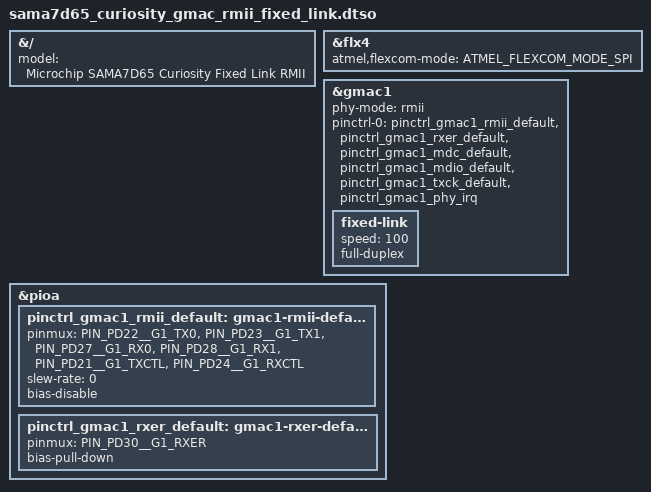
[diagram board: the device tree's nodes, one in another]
// SPDX-License-Identifier: (GPL-2.0+ OR MIT)
/*
 *  Device Tree overlay for the SAMA7D65-CURIOSITY board
 *  to use fixed link RMII.
 *
 *  Copyright (c) 2026 Microchip Technology Inc. and its subsidiaries
 *
 *  Author: Joemel John A. Diente <JoemelJohn.Diente@microchip.com>
 *
 */
/dts-v1/;
/plugin/;
#include "sama7d65-pinfunc.h"
#include <dt-bindings/mfd/atmel-flexcom.h>
#include <dt-bindings/clock/at91.h>
#include <dt-bindings/pinctrl/at91.h>
#include <dt-bindings/gpio/gpio.h>
#include <dt-bindings/interrupt-controller/irq.h>

&{/}
{
	model = "Microchip SAMA7D65 Curiosity Fixed Link RMII";
};

&flx4 {
	atmel,flexcom-mode = <ATMEL_FLEXCOM_MODE_SPI>;
	status = "okay";
};

&gmac1 {
	phy-mode = "rmii";
	pinctrl-names = "default";
	pinctrl-0 = <&pinctrl_gmac1_rmii_default
		     &pinctrl_gmac1_rxer_default
		     &pinctrl_gmac1_mdc_default
		     &pinctrl_gmac1_mdio_default
		     &pinctrl_gmac1_txck_default
		     &pinctrl_gmac1_phy_irq>;
	// cdns,refclk-ext;
	status = "okay";

	fixed-link {
		speed = <100>;
		full-duplex;
	};
};

&pioa {
	pinctrl_gmac1_rmii_default: gmac1-rmii-default{
		pinmux = <PIN_PD22__G1_TX0>,
			 <PIN_PD23__G1_TX1>,
			 <PIN_PD27__G1_RX0>,
			 <PIN_PD28__G1_RX1>,
			 <PIN_PD21__G1_TXCTL>,
			 <PIN_PD24__G1_RXCTL>;
		slew-rate = <0>;
		bias-disable;
	};

	pinctrl_gmac1_rxer_default: gmac1-rxer-default{
		pinmux = <PIN_PD30__G1_RXER>;	/* ETH_RXER in RMII  */
		bias-pull-down;
	};
};
